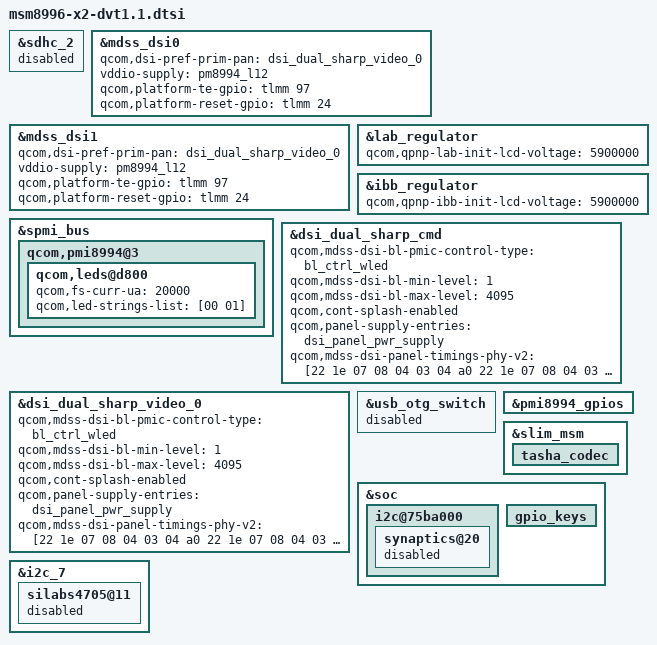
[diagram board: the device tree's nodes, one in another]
/* Copyright (c) 2015, The Linux Foundation. All rights reserved.
 *
 * This program is free software; you can redistribute it and/or modify
 * it under the terms of the GNU General Public License version 2 and
 * only version 2 as published by the Free Software Foundation.
 *
 * This program is distributed in the hope that it will be useful,
 * but WITHOUT ANY WARRANTY; without even the implied warranty of
 * MERCHANTABILITY or FITNESS FOR A PARTICULAR PURPOSE.  See the
 * GNU General Public License for more details.
 */

#include "msm8996-mtp-le-common.dtsi"
#include "msm8996-pinctrl-x2.dtsi"
#include "dsi-panel-sharp-dualmipi-cmd.dtsi"
#include "dsi-panel-sharp-dualmipi-video.dtsi"
#include "letv-tp-atmel_mxt_ts.dtsi"
#include "msm8996-camera-sensor-x2-dvt1.1.dtsi"

&sdhc_2 {
	status = "disabled";
};

&mdss_dsi0 {
	qcom,dsi-pref-prim-pan = <&dsi_dual_sharp_video_0>;
	vddio-supply = <&pm8994_l12>;
	qcom,platform-te-gpio = <&tlmm 97 0>;
	qcom,platform-reset-gpio = <&tlmm 24 0>;
	/delete-property/ qcom,platform-bklight-en-gpio;
};

&mdss_dsi1 {
	qcom,dsi-pref-prim-pan = <&dsi_dual_sharp_video_0>;
	vddio-supply = <&pm8994_l12>;
	qcom,platform-te-gpio = <&tlmm 97 0>;
	qcom,platform-reset-gpio = <&tlmm 24 0>;
	/delete-property/ qcom,platform-bklight-en-gpio;
};

&lab_regulator {
	qcom,qpnp-lab-init-lcd-voltage = <5900000>;
};

&ibb_regulator {
	qcom,qpnp-ibb-init-lcd-voltage = <5900000>;
};

&spmi_bus {
	qcom,pmi8994@3 {
		qcom,leds@d800 {
			qcom,fs-curr-ua = <20000>;
			qcom,led-strings-list = [00 01];
		};
	};
};

&dsi_dual_sharp_cmd {
	qcom,mdss-dsi-bl-pmic-control-type = "bl_ctrl_wled";
	qcom,mdss-dsi-bl-min-level = <1>;
	qcom,mdss-dsi-bl-max-level = <4095>;
	qcom,cont-splash-enabled;
	qcom,panel-supply-entries = <&dsi_panel_pwr_supply>;

	qcom,mdss-dsi-panel-timings-phy-v2 = [22 1e 07 08 04 03 04 a0
		22 1e 07 08 04 03 04 a0
		22 1e 07 08 04 03 04 a0
		22 1e 07 08 04 03 04 a0
		23 17 06 08 05 03 04 a0];
};

&dsi_dual_sharp_video_0 {
	qcom,mdss-dsi-bl-pmic-control-type = "bl_ctrl_wled";
	qcom,mdss-dsi-bl-min-level = <1>;
	qcom,mdss-dsi-bl-max-level = <4095>;
	qcom,cont-splash-enabled;
	qcom,panel-supply-entries = <&dsi_panel_pwr_supply>;

	qcom,mdss-dsi-panel-timings-phy-v2 = [22 1e 07 08 04 03 04 a0
		22 1e 07 08 04 03 04 a0
		22 1e 07 08 04 03 04 a0
		22 1e 07 08 04 03 04 a0
		23 17 06 08 05 03 04 a0];
};

&usb_otg_switch {
	status = "disabled";
};

&pmi8994_gpios {
	/delete-node/ gpio@c100; /* PMI8994 GPIO 2 */
	/delete-node/ gpio@c200; /* PMI8994 GPIO 3 */
};

&slim_msm {
	/delete-node/ tomtom_codec;
	tasha_codec {
		/delete-node/ wsa881x@20170212;
		/delete-node/ wsa881x@20170211;
	};
};

&soc {
	i2c@75ba000 {
		synaptics@20 {
			status = "disabled";
		};
	};

	/delete-node/ gen-vkeys;

	gpio_keys {
		/delete-node/ cam_focus;
	};

	/delete-node/ sound;

	/delete-node/ flash_led;
};

&i2c_7 {
	silabs4705@11 { /* SiLabs FM chip, slave id 0x11*/
		status = "disabled";
	};
};
